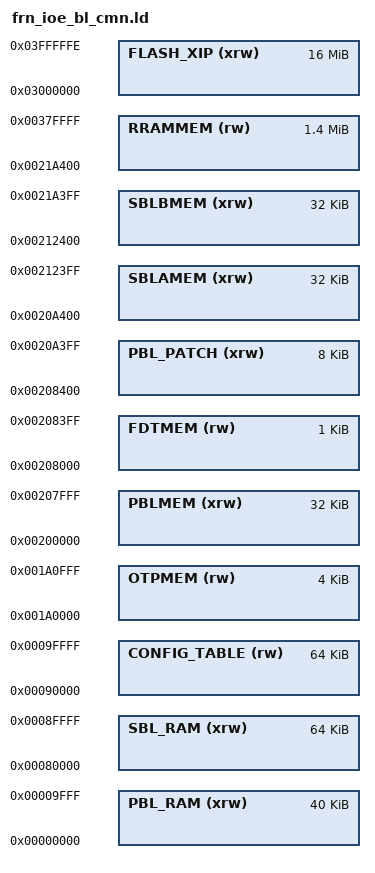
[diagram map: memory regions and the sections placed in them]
/*
 * Copyright (c) 2024 Qualcomm Innovation Center, Inc. All rights reserved.
 * SPDX-License-Identifier: BSD-3-Clause-Clear
*/

/*
 * Memory Spaces Definitions.
 */


MEMORY
{
  OTPMEM (rw) : ORIGIN = 0x001A0000, LENGTH = 0x00001000
  PBLMEM (xrw) : ORIGIN = 0x00200000, LENGTH = 0x00008000
  FDTMEM (rw) : ORIGIN = 0x00208000, LENGTH = 0x00000400
  PBL_PATCH (xrw) : ORIGIN = 0x00208400, LENGTH = 0x00002000
  SBLAMEM (xrw) : ORIGIN = 0x0020A400, LENGTH = 0x00008000
  SBLBMEM (xrw) : ORIGIN = 0x00212400, LENGTH = 0x00008000
  RRAMMEM (rw) : ORIGIN = 0x0021A400, LENGTH = 0x00165C00
  PBL_RAM (xrw) : ORIGIN = 0x00000000, LENGTH = 0x0000A000
  SBL_RAM (xrw) : ORIGIN = 0x00080000, LENGTH = 0x00010000
  CONFIG_TABLE (rw) : ORIGIN = 0x00090000, LENGTH = 0x00010000
  FLASH_XIP (xrw) : ORIGIN = 0x003000000, LENGTH = 0x00ffffff
}

/* FDT start address*/
_FDT_Start_Addr = ORIGIN(FDTMEM);

/* SBLA image start address*/
_SBLA_IMAGE_Start_Addr = ORIGIN(SBLAMEM);
